# STMP3770 register map
Vendor: Freescale Semiconductor (NXP); Series: STMP37xx; File version: 1.0
CPU: other r0p0, little endian, no MPU, no FPU, 2 interrupt priority bits
Registers are 32-bit, read-write, reset 0x0 unless marked. A register's access mark holds for its fields unless they carry their own. Offsets are from the block's base; [hi:lo] are bit positions; {n}, {i} and the like mark numbered series.

## USBCTRL — ChipIdea/MXS USB 2.0 OTG 控制器（EHCI 兼容扩展），HP39GII 工作于 Device 模式。包含 EHCI 能力寄存器、USB 命令/状态/中断控制、端点队列管理（QH）、端口状态控制、OTG 状态控制及端点控制寄存器组。
Base 0x80080000
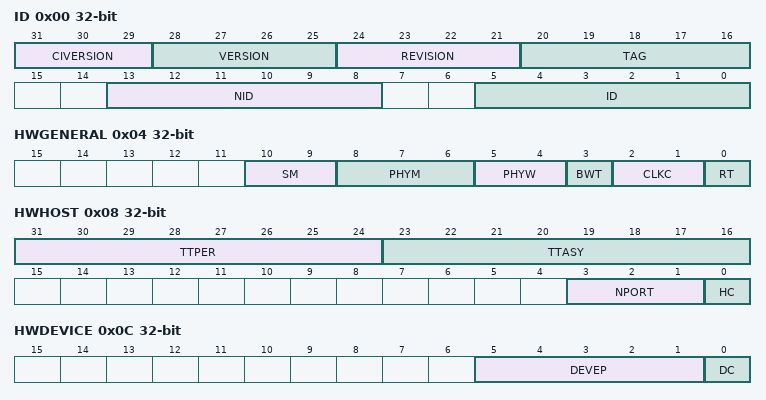
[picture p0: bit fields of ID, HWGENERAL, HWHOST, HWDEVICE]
0x00 ID — Identification Register
  [31:29] CIVERSION — ChipIdea 接口版本号（只读）
  [28:25] VERSION — USB 控制器版本号（只读）
  [24:21] REVISION — 硅片修订版本号（只读）
  [20:16] TAG — 架构版本标签（只读）
  [13:8] NID — ID 取反码（只读）
  [5:0] ID — USB 控制器 ID 标识码（只读）
0x04 HWGENERAL — General Hardware Parameters Register
  [10:9] SM — 串行模式选择（只读）
  [8:6] PHYM — PHY 模式（只读）
  [5:4] PHYW — PHY 数据宽度（只读）
  [3] BWT — 总线等待时间配置（只读）
  [2:1] CLKC — 时钟配置（只读）
  [0] RT — 保留测试模式（只读）
0x08 HWHOST — Host Hardware Parameters Register
  [31:24] TTPER — TT 周期性调度延迟（只读）
  [23:16] TTASY — TT 异步调度延迟（只读）
  [3:1] NPORT — 端口数量（只读）
  [0] HC — Host 模式支持标志（只读）
0x0C HWDEVICE — Device Hardware Parameters Register
  [5:1] DEVEP — 支持的 Device 端点数量（只读）
  [0] DC — Device 模式支持标志（只读）
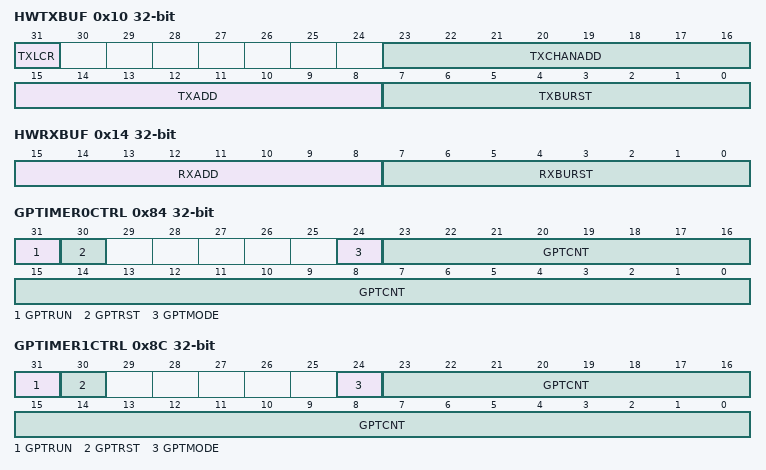
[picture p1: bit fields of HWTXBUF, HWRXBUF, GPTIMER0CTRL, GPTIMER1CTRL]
0x10 HWTXBUF — TX Buffer Hardware Parameters Register
  [31] TXLCR — TX 本地上下文重排使能（只读）
  [23:16] TXCHANADD — TX 每通道缓冲区大小（只读）
  [15:8] TXADD — TX 缓冲区总大小（只读）
  [7:0] TXBURST — TX 突发传输长度（只读）
0x14 HWRXBUF — RX Buffer Hardware Parameters Register
  [15:8] RXADD — RX 缓冲区总大小（只读）
  [7:0] RXBURST — RX 突发传输长度（只读）
0x80 GPTIMER0LD — General-Purpose Timer 0 Load (Non-EHCI-Compliant) Register
  [23:0] GPTLD — 通用定时器 0 加载值（24 位递减计数初值）
0x84 GPTIMER0CTRL — General-Purpose Timer 0 Control (Non-EHCI-Compliant) Register
  [31] GPTRUN — 通用定时器 0 运行控制（0=停止 STOP，1=运行 RUN）
    0=STOP; 1=RUN
  [30] GPTRST — 通用定时器 0 复位（0=无操作，1=加载 GPTLD 到计数器）
    0=NOACTION; 1=LOADCOUNTER
  [24] GPTMODE — 通用定时器 0 工作模式（0=单次 ONESHOT，1=重复 REPEAT）
    0=ONESHOT; 1=REPEAT
  [23:0] GPTCNT — 通用定时器 0 当前计数值（24 位，只读）
0x88 GPTIMER1LD — General-Purpose Timer 1 Load (Non-EHCI-Compliant) Register
  [23:0] GPTLD — 通用定时器 1 加载值（24 位递减计数初值）
0x8C GPTIMER1CTRL — General-Purpose Timer 1 Control (Non-EHCI-Compliant) Register
  [31] GPTRUN — 通用定时器 1 运行控制（0=停止 STOP，1=运行 RUN）
    0=STOP; 1=RUN
  [30] GPTRST — 通用定时器 1 复位（0=无操作，1=加载 GPTLD 到计数器）
    0=NOACTION; 1=LOADCOUNTER
  [24] GPTMODE — 通用定时器 1 工作模式（0=单次 ONESHOT，1=重复 REPEAT）
    0=ONESHOT; 1=REPEAT
  [23:0] GPTCNT — 通用定时器 1 当前计数值（24 位，只读）
0x90 SBUSCFG — System Bus Configuration (Non-EHCI-Compliant) Register
  [2:0] AHBBRST — AHB 总线突发传输模式（INCR/INCR4/INCR8/INCR16 等）
    0=U_INCR; 1=S_INCR4; 2=S_INCR8; 3=S_INCR16; 5=U_INCR4; 6=U_INCR8; 7=U_INCR16
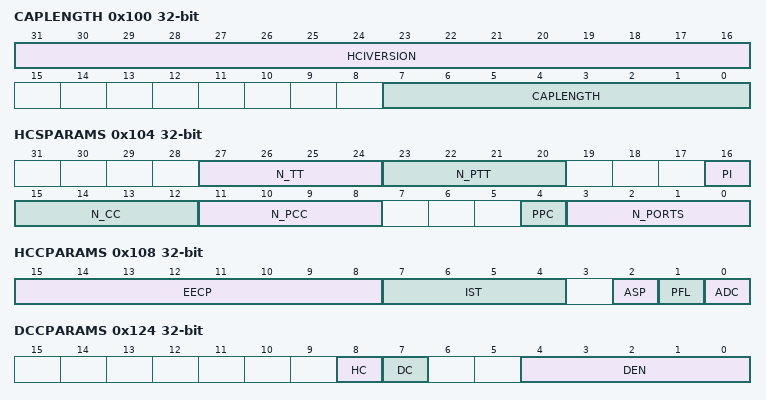
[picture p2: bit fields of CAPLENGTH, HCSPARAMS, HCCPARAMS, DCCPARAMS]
0x100 CAPLENGTH — Capability Length and HCI Version (EHCI-Compliant) Register
  [31:16] HCIVERSION — EHCI HCI 版本号（BCD 编码，只读）
  [7:0] CAPLENGTH — 能力寄存器组长度（字节数，只读）
0x104 HCSPARAMS — Host Control Structural Parameters (EHCI-Compliant with Extensions) Register
  [27:24] N_TT — Transaction Translator 数量（只读）
  [23:20] N_PTT — 每 TT 端口数（只读）
  [16] PI — 端口指示器支持（只读）
  [15:12] N_CC — Companion 控制器数量（只读）
  [11:8] N_PCC — 每 Companion 控制器端口数（只读）
  [4] PPC — 端口电源控制支持（只读）
  [3:0] N_PORTS — 物理端口数量（只读）
0x108 HCCPARAMS — Host Control Capability Parameters (EHCI-Compliant) Register
  [15:8] EECP — EHCI 扩展能力指针偏移（只读）
  [7:4] IST — 等时同步调度阈值（只读）
  [2] ASP — 异步调度 Park 能力（只读）
  [1] PFL — 可编程帧列表标志（只读）
  [0] ADC — 64 位地址映射能力（只读）
0x120 DCIVERSION ro — Device Interface Version Number (Non-EHCI-Compliant) Register
  [15:0] DCIVERSION — Device 接口版本号（BCD 编码，只读）
0x124 DCCPARAMS — Device Control Capability Parameters (Non-EHCI-Compliant) Register
  [8] HC — Host 模式支持标志（只读）
  [7] DC — Device 模式支持标志（只读）
  [4:0] DEN — Device 端点数量（只读）
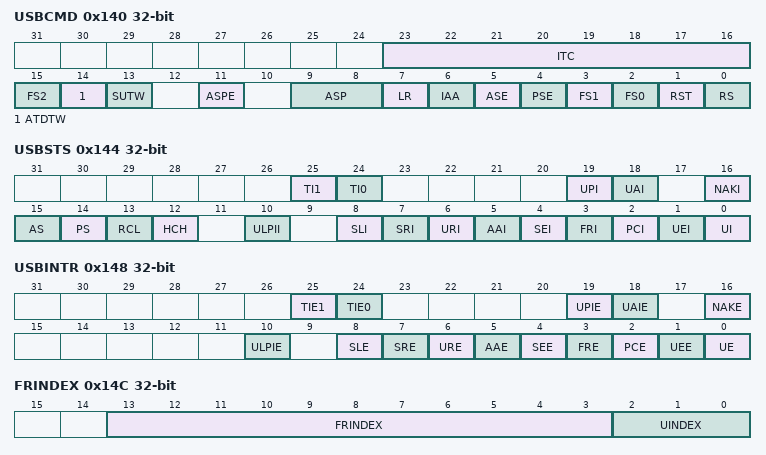
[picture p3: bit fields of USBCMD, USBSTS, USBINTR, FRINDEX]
0x140 USBCMD — USB Command Register
  [23:16] ITC — 中断阈值控制（微帧数：立即/1/2/4/8/16/32/64）
    0=IMM; 1=_1_MICROFRAME; 2=_2_MICROFRAME; 4=_4_MICROFRAME; 8=_8_MICROFRAME; 16=_16_MICROFRAME; 32=_32_MICROFRAME; 64=_64_MICROFRAME
  [15] FS2 — 帧列表大小位 2（与 FS0/FS1 组合）
  [14] ATDTW — 添加 dTD 定时写（Device 模式，用于同步 dTD 添加）
  [13] SUTW — Setup 包定时写（Device 模式，用于同步 Setup 包处理）
  [11] ASPE — 异步调度 Park 模式使能（Host 模式）
  [9:8] ASP — 异步调度 Park 模式计数（Host 模式）
  [7] LR — 中断仲裁级别控制（Host 模式）
  [6] IAA — 异步调度推进门铃（Host 模式）
  [5] ASE — 异步调度使能（Host 模式）
  [4] PSE — 周期性调度使能（Host 模式）
  [3] FS1 — 帧列表大小位 1（与 FS0/FS2 组合）
  [2] FS0 — 帧列表大小位 0（与 FS1/FS2 组合）
  [1] RST — 控制器软复位，写 1 复位所有内部状态机
  [0] RS — Run/Stop，控制器运行（1）或停止（0）并连接总线
0x144 USBSTS — USB Status Register
  [25] TI1 — 通用定时器 1 中断
  [24] TI0 — 通用定时器 0 中断
  [19] UPI — USB 主机周期性中断
  [18] UAI — USB 主机异步中断
  [16] NAKI — NAK 中断（Device 模式，端点 NAK 事件）
  [15] AS — 异步调度状态（只读）
  [14] PS — 周期性调度状态（只读）
  [13] RCL — 异步调度回收中（只读）
  [12] HCH — 主机控制器已停止（只读）
  [10] ULPII — ULPI 中断
  [8] SLI — 挂起中断（Device 模式，总线挂起事件）
  [7] SRI — SOF 接收中断（Device 模式，收到 Start-of-Frame）
  [6] URI — USB 复位中断（Device 模式，总线复位事件）
  [5] AAI — 异步调度推进中断（Host 模式）
  [4] SEI — 系统错误中断
  [3] FRI — 帧列表滚动中断（Host 模式）
  [2] PCI — 端口变化中断（Host 模式，端口状态变化）
  [1] UEI — USB 错误中断（传输错误）
  [0] UI — USB 中断（传输完成等事件）
0x148 USBINTR — USB Interrupt Enable Register
  [25] TIE1 — 通用定时器 1 中断使能（对应 TI1）
  [24] TIE0 — 通用定时器 0 中断使能（对应 TI0）
  [19] UPIE — USB 主机周期性中断使能（对应 UPI）
  [18] UAIE — USB 主机异步中断使能（对应 UAI）
  [16] NAKE — NAK 中断使能（对应 NAKI）
  [10] ULPIE — ULPI 中断使能（对应 ULPII）
  [8] SLE — 挂起中断使能（对应 SLI）
  [7] SRE — SOF 接收中断使能（对应 SRI）
  [6] URE — USB 复位中断使能（对应 URI）
  [5] AAE — 异步调度推进中断使能（对应 AAI）
  [4] SEE — 系统错误中断使能（对应 SEI）
  [3] FRE — 帧列表滚动中断使能（对应 FRI）
  [2] PCE — 端口变化中断使能（对应 PCI）
  [1] UEE — USB 错误中断使能（对应 UEI）
  [0] UE — USB 中断使能（对应 UI）
0x14C FRINDEX — USB Frame Index Register
  [13:3] FRINDEX — 帧索引（当前帧号，与帧列表配合）
    {v}=N_{v} (v=5..12)
  [2:0] UINDEX — 微帧索引（当前微帧号，0-7）
0x154 PERIODICLISTBASE (alternate view of DEVICEADDR) — Frame List Base Address Register (Host Controller mode)
  [31:12] PERBASE — 周期性帧列表基地址（4K 对齐，Host 模式）
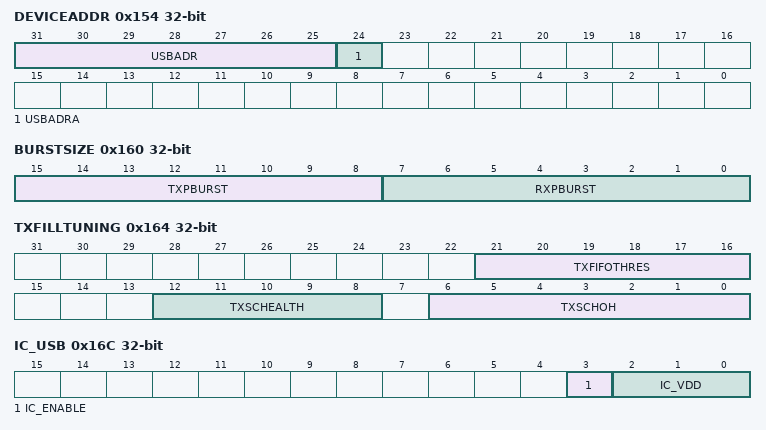
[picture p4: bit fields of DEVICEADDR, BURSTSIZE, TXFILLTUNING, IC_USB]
0x154 DEVICEADDR — USB Device Address Register (Device Controller mode)。注：该物理地址在 Host 模式下为 PERIODICLISTBASE。
  [31:25] USBADR — USB 设备地址（7 位，Device 模式）
  [24] USBADRA — USB 设备地址立即生效（写 1 使 USBADR 立即生效）
0x158 ASYNCLISTADDR (alternate view of ENDPOINTLISTADDR) — Next Asynchronous Address Register (Host Controller mode)
  [31:5] ASYBASE — 异步列表下一队列头基地址（32 字节对齐，Host 模式）
0x158 ENDPOINTLISTADDR — Endpoint List Address Register (Device Controller mode)。注：该物理地址在 Host 模式下为 ASYNCLISTADDR。
  [31:11] EPBASE — 端点队列头（QH）列表基地址（2K 对齐，Device 模式）
0x15C TTCTRL — Embedded TT Asynchronous Buffer Status and Control Register (Host Controller mode)
  [30:24] TTHA — TT 异步缓冲区水位线（Host 模式）
0x160 BURSTSIZE — Programmable Burst Size Register
  [15:8] TXPBURST — TX 突发传输长度（一次 AHB 突发中写的数据 beats 数）
  [7:0] RXPBURST — RX 突发传输长度（一次 AHB 突发中读的数据 beats 数）
0x164 TXFILLTUNING — Host Transmit Pre-Buffer Packet Timing Register
  [21:16] TXFIFOTHRES — TX FIFO 阈值（Host 模式，预缓冲包触发阈值）
  [12:8] TXSCHEALTH — TX 调度健康计数器（Host 模式）
  [6:0] TXSCHOH — TX 调度过载健康计数（Host 模式）
0x16C IC_USB — Inter-Chip Control Register
  [3] IC_ENABLE — Inter-Chip 接口使能
  [2:0] IC_VDD — Inter-Chip 接口电压选择（0=无/1.0V/1.2V/1.5V/1.8V/3.0V 等）
    0=VOLTAGE_NONE; 1=VOLTAGE_1_0; 2=VOLTAGE_1_2; 3=VOLTAGE_1_5; 4=VOLTAGE_1_8; 5=VOLTAGE_3_0
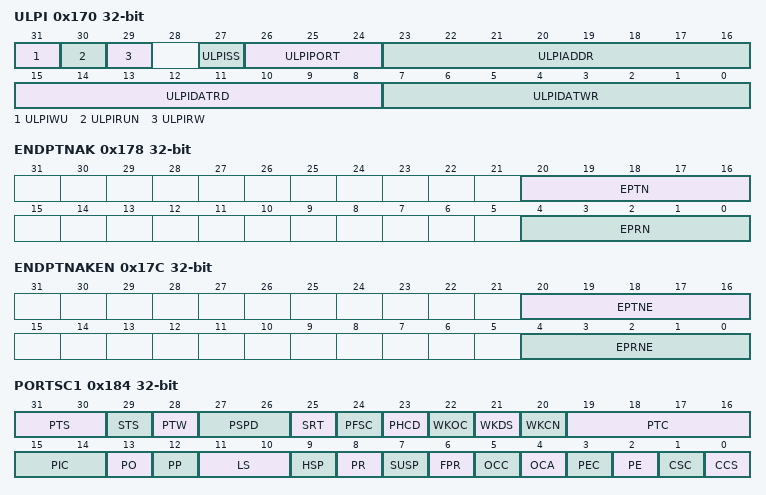
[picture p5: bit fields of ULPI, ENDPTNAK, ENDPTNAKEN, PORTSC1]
0x170 ULPI — ULPI Viewport Register
  [31] ULPIWU — ULPI 唤醒（写 1 发送 ULPI 唤醒信号）
  [30] ULPIRUN — ULPI 运行（写 1 启动 ULPI 事务，完成后硬件清零）
  [29] ULPIRW — ULPI 读写方向（0=读，1=写）
  [27] ULPISS — ULPI 状态（0=空闲，1=忙，只读）
  [26:24] ULPIPORT — ULPI 端口选择
  [23:16] ULPIADDR — ULPI 寄存器地址（要访问的 ULPI 寄存器地址）
  [15:8] ULPIDATRD — ULPI 数据读（ULPI 寄存器读返回的数据，只读）
  [7:0] ULPIDATWR — ULPI 数据写（发起 ULPI 寄存器写时的数据）
0x178 ENDPTNAK — Endpoint NAK Register
  [20:16] EPTN — TX 端点 NAK 状态（5 位，每 bit 对应一个端点，只读）
  [4:0] EPRN — RX 端点 NAK 状态（5 位，每 bit 对应一个端点，只读）
0x17C ENDPTNAKEN — Endpoint NAK Enable Register
  [20:16] EPTNE — TX 端点 NAK 中断使能（5 位，每 bit 对应一个端点）
  [4:0] EPRNE — RX 端点 NAK 中断使能（5 位，每 bit 对应一个端点）
0x184 PORTSC1 — Port Status and Control 1 Register
  [31:30] PTS — PHY 收发器选择（UTMI/PHIL/ULPI/SERIAL）
    0=UTMI; 1=PHIL; 2=ULPI; 3=SERIAL
  [29] STS — 串行收发器选择状态
  [28] PTW — 端口 16 位 UTMI 宽度（1=使用 16 位数据宽度）
  [27:26] PSPD — 端口速度（FULL/LOW/HIGH，只读）
    0=FULL; 1=LOW; 2=HIGH
  [25] SRT — 串行收发器选择
  [24] PFSC — 强制全速（1=强制端口工作于全速）
  [23] PHCD — PHY 时钟关闭（1=关闭 PHY 时钟以省电）
  [22] WKOC — 过流唤醒使能
  [21] WKDS — 断开唤醒使能
  [20] WKCN — 连接唤醒使能（远程唤醒检测）
  [19:16] PTC — 端口测试控制（TEST_DISABLE/J_STATE/K_STATE/PACKET 等）
    0=TEST_DISABLE; 1=TEST_J_STATE; 2=TEST_K_STATE; 3=TEST_J_SE0_NAK; 4=TEST_PACKET; 5=TEST_FORCE_ENABLE_HS; 6=TEST_FORCE_ENABLE_FS; 7=TEST_FORCE_ENABLE_LS
  [15:14] PIC — 端口指示器颜色（OFF/AMBER/GREEN，配合 PI 使用）
    0=OFF; 1=AMBER; 2=GREEN; 3=UNDEF
  [13] PO — 端口拥有者（Host 模式，Companion/HC 切换）
  [12] PP — 端口电源（1=端口供电）
  [11:10] LS — 线路状态（SE0/K_STATE/J_STATE/UNDEF，反映 D+/D- 电平）
    0=SE0; 1=K_STATE; 2=J_STATE; 3=UNDEF
  [9] HSP — 高速端口（1=端口工作于高速，只读）
  [8] PR — 端口复位（写 1 启动端口复位，10ms 后硬件清零）
  [7] SUSP — 挂起状态（1=端口已挂起）
  [6] FPR — 强制端口恢复（写 1 从挂起恢复）
  [5] OCC — 过流变化（写 1 清零）
  [4] OCA — 过流状态（1=检测到过流，只读）
  [3] PEC — 端口使能变化（写 1 清零）
  [2] PE — 端口使能（1=端口已使能）
  [1] CSC — 连接状态变化（写 1 清零）
  [0] CCS — 当前连接状态（1=设备已连接，只读）
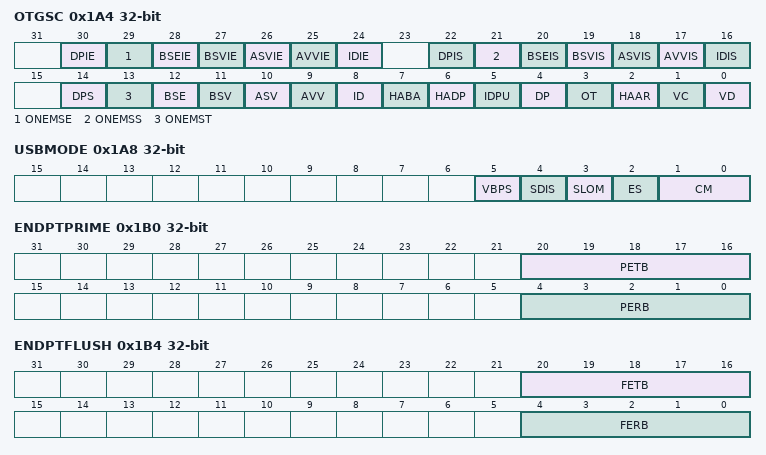
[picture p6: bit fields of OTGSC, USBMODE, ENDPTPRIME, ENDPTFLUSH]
0x1A4 OTGSC — OTG Status and Control Register
  [30] DPIE — 数据脉冲中断使能
  [29] ONEMSE — 1 毫秒定时器中断使能
  [28] BSEIE — B 设备会话结束中断使能
  [27] BSVIE — B 设备会话有效中断使能
  [26] ASVIE — A 设备会话有效中断使能
  [25] AVVIE — A 设备 VBUS 有效中断使能
  [24] IDIE — ID 中断使能
  [22] DPIS — 数据脉冲中断状态（写 1 清零）
  [21] ONEMSS — 1 毫秒定时器中断状态（写 1 清零）
  [20] BSEIS — B 设备会话结束中断状态（写 1 清零）
  [19] BSVIS — B 设备会话有效中断状态（写 1 清零）
  [18] ASVIS — A 设备会话有效中断状态（写 1 清零）
  [17] AVVIS — A 设备 VBUS 有效中断状态（写 1 清零）
  [16] IDIS — ID 中断状态（写 1 清零）
  [14] DPS — 数据脉冲状态（只读）
  [13] ONEMST — 1 毫秒定时器（1ms 定时器状态，只读）
  [12] BSE — B 设备会话结束（1=会话结束，只读）
  [11] BSV — B 设备会话有效（1=会话有效，只读）
  [10] ASV — A 设备会话有效（1=会话有效，只读）
  [9] AVV — A 设备 VBUS 有效（1=VBUS 有效，只读）
  [8] ID — ID 状态（0=A 设备，1=B 设备，只读）
  [7] HABA — 主机 A 设备 B 设备自动（Host 模式自动切换）
  [6] HADP — 主机 A 设备断开脉冲（Host 模式 A 设备断开检测）
  [5] IDPU — ID 上拉使能（1=使能 ID 线上拉）
  [4] DP — 数据脉冲（写 1 发送数据脉冲）
  [3] OT — OTG 终止（终止 OTG 会话）
  [2] HAAR — 辅助 A 设备自动重试（Host 模式 A 设备自动重试）
  [1] VC — VBUS 充电（写 1 对 VBUS 充电）
  [0] VD — VBUS 放电（写 1 对 VBUS 放电）
0x1A8 USBMODE — USB Device Mode Register
  [5] VBPS — VBUS 电源选择
  [4] SDIS — 流 ID 禁用（禁用流 ID 功能）
  [3] SLOM — Setup 锁存模式（1=Setup 包不覆盖已有 dTD）
  [2] ES — 端点排序（1=大端模式，0=小端模式）
  [1:0] CM — 控制器模式（0=空闲 IDLE，2=Device，3=Host，0x1 保留）
    0=IDLE; 2=DEVICE; 3=HOST
0x1AC ENDPTSETUPSTAT — Endpoint Setup Status Register
  [4:0] ENDPTSETUPSTAT — 端点 Setup 包到达状态（5 位，每 bit 对应一个端点，写 1 清零）
0x1B0 ENDPTPRIME — Endpoint Initialization Register
  [20:16] PETB — TX 端点 PRIME（5 位，每 bit 对应一个端点，写 1 请求硬件准备发送缓冲区）
  [4:0] PERB — RX 端点 PRIME（5 位，每 bit 对应一个端点，写 1 请求硬件准备接收缓冲区）
0x1B4 ENDPTFLUSH — Endpoint De-Initialize Register
  [20:16] FETB — TX 端点 FLUSH（5 位，每 bit 对应一个端点，写 1 刷新 TX 端点缓冲区）
  [4:0] FERB — RX 端点 FLUSH（5 位，每 bit 对应一个端点，写 1 刷新 RX 端点缓冲区）
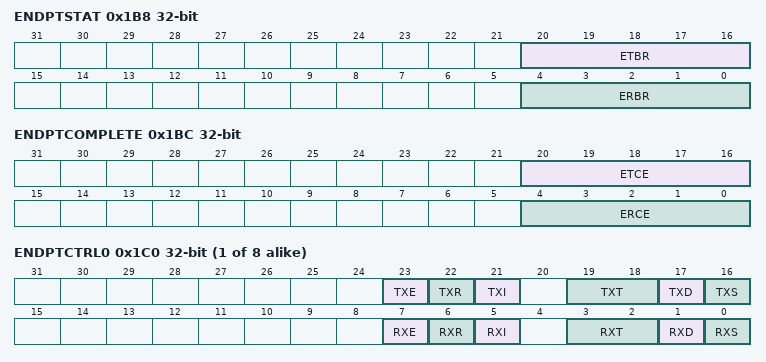
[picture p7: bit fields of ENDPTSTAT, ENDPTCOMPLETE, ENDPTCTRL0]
0x1B8 ENDPTSTAT — Endpoint Status Register
  [20:16] ETBR — TX 端点缓冲区就绪（5 位，每 bit 对应一个端点，只读）
  [4:0] ERBR — RX 端点缓冲区就绪（5 位，每 bit 对应一个端点，只读）
0x1BC ENDPTCOMPLETE — Endpoint Complete Register
  [20:16] ETCE — TX 端点传输完成（5 位，每 bit 对应一个端点，写 1 清零）
  [4:0] ERCE — RX 端点传输完成（5 位，每 bit 对应一个端点，写 1 清零）
{0x1C0+4i} ENDPTCTRL{i} (i=0..7)
  [23] TXE — TX 端点使能（1=使能 TX 端点）
  [22] TXR — TX 端点数据切换复位（写 1 复位数据切换序列为 DATA0）
  [21] TXI — TX 端点数据切换禁止（写 1 禁止硬件自动数据切换）
  [19:18] TXT — TX 端点类型（00=控制/01=等时/10=批量/11=中断）
    0=CONTROL; 1=ISO; 2=BULK; 3=INT
  [17] TXD — TX 端点数据切换（只读，反映当前数据切换状态）
  [16] TXS — TX 端点 STALL（1=TX 端点发送 STALL 握手）
  [7] RXE — RX 端点使能（1=使能 RX 端点）
  [6] RXR — RX 端点数据切换复位（写 1 复位数据切换序列为 DATA0）
  [5] RXI — RX 端点数据切换禁止（写 1 禁止硬件自动数据切换）
  [3:2] RXT — RX 端点类型（00=控制/01=等时/10=批量/11=中断）
    0=CONTROL; 1=ISO; 2=BULK; 3=INT
  [1] RXD — RX 端点数据切换（只读，反映当前数据切换状态）
  [0] RXS — RX 端点 STALL（1=RX 端点发送 STALL 握手）
